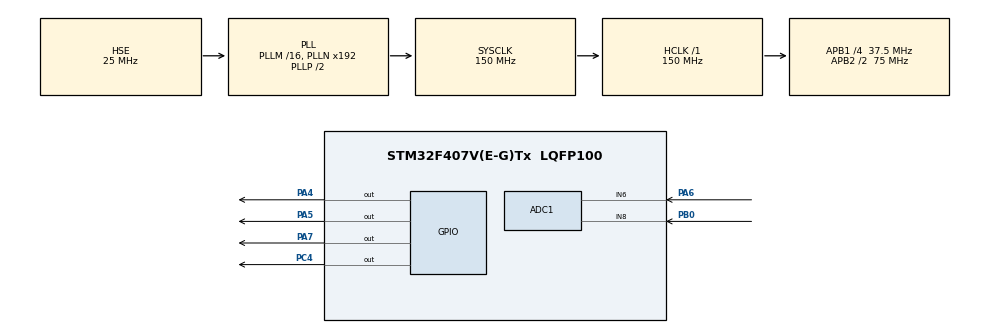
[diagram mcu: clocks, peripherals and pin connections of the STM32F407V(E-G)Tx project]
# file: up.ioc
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ADC1.Channel-1\#ChannelRegularConversion=ADC_CHANNEL_6
ADC1.Channel-2\#ChannelRegularConversion=ADC_CHANNEL_8
ADC1.ContinuousConvMode=ENABLE
ADC1.DMAContinuousRequests=ENABLE
ADC1.InjNumberOfConversion=0
ADC1.NbrOfConversion=2
ADC1.NbrOfConversionFlag=1
ADC1.Rank-1\#ChannelRegularConversion=1
ADC1.Rank-2\#ChannelRegularConversion=2
ADC1.SamplingTime-1\#ChannelRegularConversion=ADC_SAMPLETIME_3CYCLES
ADC1.SamplingTime-2\#ChannelRegularConversion=ADC_SAMPLETIME_3CYCLES
ADC1.master=1
Dma.ADC1.0.Direction=DMA_PERIPH_TO_MEMORY
Dma.ADC1.0.FIFOMode=DMA_FIFOMODE_DISABLE
Dma.ADC1.0.Instance=DMA2_Stream0
Dma.ADC1.0.MemDataAlignment=DMA_MDATAALIGN_WORD
Dma.ADC1.0.MemInc=DMA_MINC_ENABLE
Dma.ADC1.0.Mode=DMA_CIRCULAR
Dma.ADC1.0.PeriphDataAlignment=DMA_PDATAALIGN_WORD
Dma.ADC1.0.PeriphInc=DMA_PINC_DISABLE
Dma.ADC1.0.Priority=DMA_PRIORITY_LOW
Dma.Request0=ADC1
Mcu.Family=STM32F4
Mcu.Name=STM32F407V(E-G)Tx
Mcu.Package=LQFP100
NVIC.DMA2_Stream0_IRQn=true\:1\:0\:true\:false\:true\:false\:true
NVIC.PriorityGroup=NVIC_PRIORITYGROUP_4
NVIC.TIM3_IRQn=true\:0\:0\:false\:false\:true\:true\:true
PA4.Signal=GPIO_Output
PA5.Signal=GPIO_Output
PA6.Signal=ADCx_IN6
PA7.Signal=GPIO_Output
PB0.Signal=ADCx_IN8
PC4.Signal=GPIO_Output
PH0-OSC_IN.Mode=HSE-External-Oscillator
PH0-OSC_IN.Signal=RCC_OSC_IN
PH1-OSC_OUT.Mode=HSE-External-Oscillator
PH1-OSC_OUT.Signal=RCC_OSC_OUT
ProjectManager.HeapSize=0x200
ProjectManager.StackSize=0x400
ProjectManager.TargetToolchain=MDK-ARM V5
RCC.48MHZClocksFreq_Value=75000000
RCC.AHBFreq_Value=150000000
RCC.APB1CLKDivider=RCC_HCLK_DIV4
RCC.APB1Freq_Value=37500000
RCC.APB1TimFreq_Value=75000000
RCC.APB2CLKDivider=RCC_HCLK_DIV2
RCC.APB2Freq_Value=75000000
RCC.APB2TimFreq_Value=150000000
RCC.CortexFreq_Value=150000000
RCC.HCLKFreq_Value=150000000
RCC.HSE_VALUE=25000000
RCC.HSI_VALUE=16000000
RCC.LSE_VALUE=32768
RCC.PLLSourceVirtual=RCC_PLLSOURCE_HSE
RCC.SYSCLKFreq_VALUE=150000000
RCC.SYSCLKSource=RCC_SYSCLKSOURCE_PLLCLK
RCC.VCOOutputFreq_Value=300000000
SH.ADCx_IN6.0=ADC1_IN6,IN6
SH.ADCx_IN8.0=ADC1_IN8,IN8
TIM3.Period=10-1
TIM3.Prescaler=15-1
VP_TIM3_VS_ClockSourceINT.Mode=Internal
board=custom

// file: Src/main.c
/* USER CODE BEGIN Header */
/**
  ******************************************************************************
  * @file           : main.c
  * @brief          : Main program body
  ******************************************************************************
  * @attention
  *
  * <h2><center>&copy; Copyright (c) 2019 STMicroelectronics.
  * All rights reserved.</center></h2>
  *
  * This software component is licensed by ST under BSD 3-Clause license,
  * the "License"; You may not use this file except in compliance with the
  * License. You may obtain a copy of the License at:
  *                        opensource.org/licenses/BSD-3-Clause
  *
  ******************************************************************************
  */
/* USER CODE END Header */

#include "main.h"
#include "adc.h"
#include "dma.h"
#include "tim.h"
#include "gpio.h"

void SystemClock_Config(void);

/* USER CODE BEGIN 0 */
uint32_t adcData[100];
uint32_t capadc[1];
uint32_t capex=1230;
uint32_t timeRate=0;
uint32_t ex=1900;
uint32_t delay=0;
/* USER CODE END 0 */

int main(void)
{

  /* MCU Configuration--------------------------------------------------------*/

  /* Reset of all peripherals, Initializes the Flash interface and the Systick. */
  HAL_Init();

  /* Configure the system clock */
  SystemClock_Config();

  /* Initialize all configured peripherals */
  MX_GPIO_Init();
  MX_DMA_Init();
  MX_ADC1_Init();
  MX_TIM3_Init();
  /* USER CODE BEGIN 2 */
	HAL_TIM_Base_Start_IT(&htim3);
	timeRate=1;
	HAL_ADC_Start_DMA(&hadc1,adcData,2);
	pidInit(0.1f,0.1f,0.0f,1.0f,45.0f);
	pidInit2(0.1f,0.0f,0.0f,0.0f,15.0f);
	HAL_GPIO_WritePin(GPIOC,GPIO_PIN_4,GPIO_PIN_RESET);
  /* USER CODE END 2 */

  /* Infinite loop */
  while (1)
  {

  }
}

void SystemClock_Config(void)
{
  RCC_OscInitTypeDef RCC_OscInitStruct = {0};
  RCC_ClkInitTypeDef RCC_ClkInitStruct = {0};

  /** Configure the main internal regulator output voltage
  */
  __HAL_RCC_PWR_CLK_ENABLE();
  __HAL_PWR_VOLTAGESCALING_CONFIG(PWR_REGULATOR_VOLTAGE_SCALE1);
  /** Initializes the CPU, AHB and APB busses clocks
  */
  RCC_OscInitStruct.OscillatorType = RCC_OSCILLATORTYPE_HSE;
  RCC_OscInitStruct.HSEState = RCC_HSE_ON;
  RCC_OscInitStruct.PLL.PLLState = RCC_PLL_ON;
  RCC_OscInitStruct.PLL.PLLSource = RCC_PLLSOURCE_HSE;
  RCC_OscInitStruct.PLL.PLLM = 16;
  RCC_OscInitStruct.PLL.PLLN = 192;
  RCC_OscInitStruct.PLL.PLLP = RCC_PLLP_DIV2;
  RCC_OscInitStruct.PLL.PLLQ = 4;
  if (HAL_RCC_OscConfig(&RCC_OscInitStruct) != HAL_OK)
  {
    Error_Handler();
  }
  /** Initializes the CPU, AHB and APB busses clocks
  */
  RCC_ClkInitStruct.ClockType = RCC_CLOCKTYPE_HCLK|RCC_CLOCKTYPE_SYSCLK
                              |RCC_CLOCKTYPE_PCLK1|RCC_CLOCKTYPE_PCLK2;
  RCC_ClkInitStruct.SYSCLKSource = RCC_SYSCLKSOURCE_PLLCLK;
  RCC_ClkInitStruct.AHBCLKDivider = RCC_SYSCLK_DIV1;
  RCC_ClkInitStruct.APB1CLKDivider = RCC_HCLK_DIV4;
  RCC_ClkInitStruct.APB2CLKDivider = RCC_HCLK_DIV2;

  if (HAL_RCC_ClockConfig(&RCC_ClkInitStruct, FLASH_LATENCY_4) != HAL_OK)
  {
    Error_Handler();
  }
}

void Error_Handler(void)
{
}

/************************ (C) COPYRIGHT STMicroelectronics *****END OF FILE****/
